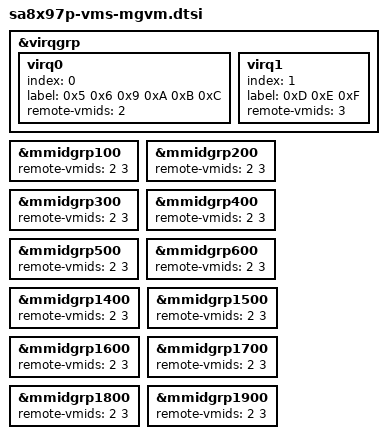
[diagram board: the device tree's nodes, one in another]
// SPDX-License-Identifier: BSD-3-Clause
/*
* Copyright (c) Qualcomm Technologies, Inc. and/or its subsidiaries.
*/
#include "sa8x97p-vms-la.dtsi"
#include "sa8x97p-vms-lv.dtsi"

&virqgrp {
	virq0 {
		index = <0>;
		label = <0x5 0x6 0x9 0xA 0xB 0xC>;
		remote-vmids = <2>;
	};

	virq1 {
		index = <1>;
		label = <0xD 0xE 0xF>;
		remote-vmids = <3>;
	};
};

&mmidgrp100 {
	remote-vmids = <2 3>;
};

&mmidgrp200 {
	remote-vmids = <2 3>;
};

&mmidgrp300 {
	remote-vmids = <2 3>;
};

&mmidgrp400 {
	remote-vmids = <2 3>;
};

&mmidgrp500 {
	remote-vmids = <2 3>;
};

&mmidgrp600 {
	remote-vmids = <2 3>;
};

&mmidgrp1400 {
	remote-vmids = <2 3>;
};

&mmidgrp1500 {
	remote-vmids = <2 3>;
};

&mmidgrp1600 {
	remote-vmids = <2 3>;
};

&mmidgrp1700 {
	remote-vmids = <2 3>;
};

&mmidgrp1800 {
	remote-vmids = <2 3>;
};

&mmidgrp1900 {
	remote-vmids = <2 3>;
};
